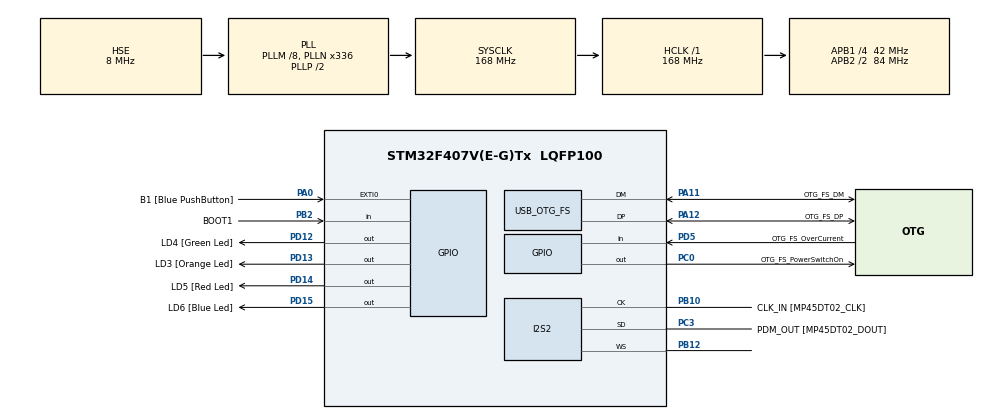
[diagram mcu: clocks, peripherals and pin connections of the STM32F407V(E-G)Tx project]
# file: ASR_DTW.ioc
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Dma.Request0=SPI2_RX
Dma.SPI2_RX.0.Channel=DMA_CHANNEL_0
Dma.SPI2_RX.0.Direction=DMA_PERIPH_TO_MEMORY
Dma.SPI2_RX.0.FIFOMode=DMA_FIFOMODE_DISABLE
Dma.SPI2_RX.0.Instance=DMA1_Stream3
Dma.SPI2_RX.0.MemDataAlignment=DMA_MDATAALIGN_HALFWORD
Dma.SPI2_RX.0.MemInc=DMA_MINC_ENABLE
Dma.SPI2_RX.0.Mode=DMA_CIRCULAR
Dma.SPI2_RX.0.PeriphDataAlignment=DMA_PDATAALIGN_HALFWORD
Dma.SPI2_RX.0.PeriphInc=DMA_PINC_DISABLE
Dma.SPI2_RX.0.Priority=DMA_PRIORITY_HIGH
FATFS._FS_LOCK=20
FATFS._FS_RPATH=2
FATFS._USE_LFN=3
FREERTOS.Tasks01=defaultTask,0,128,StartDefaultTask
FREERTOS.configCHECK_FOR_STACK_OVERFLOW=1
FREERTOS.configTOTAL_HEAP_SIZE=81920
I2S2.AudioFreq=I2S_AUDIOFREQ_32K
I2S2.ErrorAudioFreq=0.0 %
I2S2.Mode=I2S_MODE_MASTER_RX
I2S2.RealAudioFreq=32.001 KHz
I2S2.Standard=I2S_STANDARD_LSB
Mcu.Family=STM32F4
Mcu.Name=STM32F407V(E-G)Tx
Mcu.Package=LQFP100
NVIC.DMA1_Stream3_IRQn=true\:5\:0\:true
NVIC.EXTI0_IRQn=true\:15\:0\:true
NVIC.OTG_FS_IRQn=true\:6\:0\:true
NVIC.PriorityGroup=NVIC_PRIORITYGROUP_4
PA0-WKUP.GPIO_Label=B1 [Blue PushButton]
PA0-WKUP.GPIO_ModeDefaultEXTI=GPIO_MODE_IT_RISING_FALLING
PA0-WKUP.GPIO_PuPd=GPIO_NOPULL
PA0-WKUP.Signal=GPXTI0
PA11.GPIO_Label=OTG_FS_DM
PA11.GPIO_Mode=GPIO_MODE_AF_PP
PA11.GPIO_PuPd=GPIO_NOPULL
PA11.GPIO_Speed=GPIO_SPEED_HIGH
PA11.Mode=Host_Only
PA11.Signal=USB_OTG_FS_DM
PA12.GPIO_Label=OTG_FS_DP
PA12.GPIO_Mode=GPIO_MODE_AF_PP
PA12.GPIO_PuPd=GPIO_NOPULL
PA12.GPIO_Speed=GPIO_SPEED_HIGH
PA12.Mode=Host_Only
PA12.Signal=USB_OTG_FS_DP
PA13.GPIO_Label=SWDIO
PA13.Mode=Trace-Asynchronous_SW
PA13.Signal=SYS_JTMS-SWDIO
PA14.GPIO_Label=SWCLK
PA14.Mode=Trace-Asynchronous_SW
PA14.Signal=SYS_JTCK-SWCLK
PB10.GPIO_Label=CLK_IN [MP45DT02_CLK]
PB10.GPIO_Mode=GPIO_MODE_AF_PP
PB10.GPIO_PuPd=GPIO_NOPULL
PB10.GPIO_Speed=GPIO_SPEED_FAST
PB10.Mode=Half_Duplex_Master
PB10.Signal=I2S2_CK
PB12.Mode=Half_Duplex_Master
PB12.Signal=I2S2_WS
PB2.GPIO_Label=BOOT1
PB2.GPIO_Mode=GPIO_MODE_INPUT
PB2.GPIO_PuPd=GPIO_NOPULL
PB2.Signal=GPIO_Input
PB3.GPIO_Label=SWO
PB3.Mode=Trace-Asynchronous_SW
PB3.Signal=SYS_JTDO-SWO
PC0.GPIO_Label=OTG_FS_PowerSwitchOn
PC0.GPIO_ModeDefaultOutputPP=GPIO_MODE_OUTPUT_PP
PC0.GPIO_PuPd=GPIO_NOPULL
PC0.GPIO_Speed=GPIO_SPEED_LOW
PC0.Signal=GPIO_Output
PC3.GPIO_Label=PDM_OUT [MP45DT02_DOUT]
PC3.GPIO_Mode=GPIO_MODE_AF_PP
PC3.GPIO_PuPd=GPIO_NOPULL
PC3.GPIO_Speed=GPIO_SPEED_FAST
PC3.Mode=Half_Duplex_Master
PC3.Signal=I2S2_SD
PD12.GPIO_Label=LD4 [Green Led]
PD12.GPIO_ModeDefaultOutputPP=GPIO_MODE_OUTPUT_PP
PD12.GPIO_PuPd=GPIO_NOPULL
PD12.GPIO_Speed=GPIO_SPEED_LOW
PD12.Signal=GPIO_Output
PD13.GPIO_Label=LD3 [Orange Led]
PD13.GPIO_ModeDefaultOutputPP=GPIO_MODE_OUTPUT_PP
PD13.GPIO_PuPd=GPIO_NOPULL
PD13.GPIO_Speed=GPIO_SPEED_LOW
PD13.Signal=GPIO_Output
PD14.GPIO_Label=LD5 [Red Led]
PD14.GPIO_ModeDefaultOutputPP=GPIO_MODE_OUTPUT_PP
PD14.GPIO_PuPd=GPIO_NOPULL
PD14.GPIO_Speed=GPIO_SPEED_LOW
PD14.Signal=GPIO_Output
PD15.GPIO_Label=LD6 [Blue Led]
PD15.GPIO_ModeDefaultOutputPP=GPIO_MODE_OUTPUT_PP
PD15.GPIO_PuPd=GPIO_NOPULL
PD15.GPIO_Speed=GPIO_SPEED_LOW
PD15.Signal=GPIO_Output
PD5.GPIO_Label=OTG_FS_OverCurrent
PD5.GPIO_Mode=GPIO_MODE_INPUT
PD5.GPIO_PuPd=GPIO_NOPULL
PD5.Signal=GPIO_Input
PH0-OSC_IN.GPIO_Label=PH0-OSC_IN
PH0-OSC_IN.Mode=HSE-External-Oscillator
PH0-OSC_IN.Signal=RCC_OSC_IN
PH1-OSC_OUT.GPIO_Label=PH1-OSC_OUT
PH1-OSC_OUT.Mode=HSE-External-Oscillator
PH1-OSC_OUT.Signal=RCC_OSC_OUT
ProjectManager.TargetToolchain=MDK-ARM V5
RCC.48MHZClocksFreq_Value=48000000
RCC.AHBFreq_Value=168000000
RCC.APB1CLKDivider=RCC_HCLK_DIV4
RCC.APB1Freq_Value=42000000
RCC.APB1TimFreq_Value=84000000
RCC.APB2CLKDivider=RCC_HCLK_DIV2
RCC.APB2Freq_Value=84000000
RCC.APB2TimFreq_Value=168000000
RCC.CortexFreq_Value=168000000
RCC.HCLKFreq_Value=168000000
RCC.HSE_VALUE=8000000
RCC.HSI_VALUE=16000000
RCC.LSE_VALUE=32768
RCC.PLLI2SN=213
RCC.PLLM=8
RCC.PLLN=336
RCC.PLLQ=7
RCC.SYSCLKFreq_VALUE=168000000
RCC.SYSCLKSource=RCC_SYSCLKSOURCE_PLLCLK
RCC.VCOOutputFreq_Value=336000000
USB_HOST.USBH_DEBUG_LEVEL=0
USB_HOST.USBH_HandleTypeDef-MSC_FS=hUsbHostFS
USB_HOST.VirtualModeFS=Msc
USB_OTG_FS.phy_itface=HCD_PHY_EMBEDDED
VP_FATFS_VS_USB.Mode=USB
VP_FREERTOS_VS_ENABLE.Mode=Enabled
VP_USB_HOST_VS_USB_HOST_MSC_FS.Mode=MSC_FS

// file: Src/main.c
/**
  ******************************************************************************
  * File Name          : main.c
  * Date               : 03/05/2015 13:56:12
  * Description        : Main program body
  ******************************************************************************
  *
  * COPYRIGHT(c) 2015 STMicroelectronics
  *
  * Redistribution and use in source and binary forms, with or without modification,
  * are permitted provided that the following conditions are met:
  *   1. Redistributions of source code must retain the above copyright notice,
  *      this list of conditions and the following disclaimer.
  *   2. Redistributions in binary form must reproduce the above copyright notice,
  *      this list of conditions and the following disclaimer in the documentation
  *      and/or other materials provided with the distribution.
  *   3. Neither the name of STMicroelectronics nor the names of its contributors
  *      may be used to endorse or promote products derived from this software
  *      without specific prior written permission.
  *
  * THIS SOFTWARE IS PROVIDED BY THE COPYRIGHT HOLDERS AND CONTRIBUTORS "AS IS"
  * AND ANY EXPRESS OR IMPLIED WARRANTIES, INCLUDING, BUT NOT LIMITED TO, THE
  * IMPLIED WARRANTIES OF MERCHANTABILITY AND FITNESS FOR A PARTICULAR PURPOSE ARE
  * DISCLAIMED. IN NO EVENT SHALL THE COPYRIGHT HOLDER OR CONTRIBUTORS BE LIABLE
  * FOR ANY DIRECT, INDIRECT, INCIDENTAL, SPECIAL, EXEMPLARY, OR CONSEQUENTIAL
  * DAMAGES (INCLUDING, BUT NOT LIMITED TO, PROCUREMENT OF SUBSTITUTE GOODS OR
  * SERVICES; LOSS OF USE, DATA, OR PROFITS; OR BUSINESS INTERRUPTION) HOWEVER
  * CAUSED AND ON ANY THEORY OF LIABILITY, WHETHER IN CONTRACT, STRICT LIABILITY,
  * OR TORT (INCLUDING NEGLIGENCE OR OTHERWISE) ARISING IN ANY WAY OUT OF THE USE
  * OF THIS SOFTWARE, EVEN IF ADVISED OF THE POSSIBILITY OF SUCH DAMAGE.
  *
  ******************************************************************************
  */

#include "stm32f4xx_hal.h"
#include "cmsis_os.h"
#include "dma.h"
#include "fatfs.h"
#include "i2s.h"
#include "usb_host.h"
#include "gpio.h"

/* USER CODE BEGIN Includes */
#include "error_handler.h"
#include "misc.h"
/* USER CODE END Includes */

void SystemClock_Config(void);
void MX_FREERTOS_Init(void);

int main(void)
{

  /* MCU Configuration----------------------------------------------------------*/

  /* Reset of all peripherals, Initializes the Flash interface and the Systick. */
  HAL_Init();

  /* Configure the system clock */
  SystemClock_Config();

  /* Initialize all configured peripherals */
  MX_GPIO_Init();
  MX_DMA_Init();
  MX_I2S2_Init();

  /* Call init function for freertos objects (in freertos.c) */
  MX_FREERTOS_Init();

  /* Start scheduler */
  osKernelStart();

  /* We should never get here as control is now taken by the scheduler */

  /* Infinite loop */
  /* USER CODE BEGIN WHILE */
  while (1)
  {
  /* USER CODE BEGIN 3 */

	/* USER CODE END 3 */
  }

  /* USER CODE END WHILE */

}

/** System Clock Configuration
*/
void SystemClock_Config(void)
{

  RCC_OscInitTypeDef RCC_OscInitStruct;
  RCC_ClkInitTypeDef RCC_ClkInitStruct;
  RCC_PeriphCLKInitTypeDef PeriphClkInitStruct;

  __PWR_CLK_ENABLE();

  __HAL_PWR_VOLTAGESCALING_CONFIG(PWR_REGULATOR_VOLTAGE_SCALE1);

  RCC_OscInitStruct.OscillatorType = RCC_OSCILLATORTYPE_HSE;
  RCC_OscInitStruct.HSEState = RCC_HSE_ON;
  RCC_OscInitStruct.PLL.PLLState = RCC_PLL_ON;
  RCC_OscInitStruct.PLL.PLLSource = RCC_PLLSOURCE_HSE;
  RCC_OscInitStruct.PLL.PLLM = 8;
  RCC_OscInitStruct.PLL.PLLN = 336;
  RCC_OscInitStruct.PLL.PLLP = RCC_PLLP_DIV2;
  RCC_OscInitStruct.PLL.PLLQ = 7;
  HAL_RCC_OscConfig(&RCC_OscInitStruct);

  RCC_ClkInitStruct.ClockType = RCC_CLOCKTYPE_SYSCLK|RCC_CLOCKTYPE_PCLK1
                              |RCC_CLOCKTYPE_PCLK2;
  RCC_ClkInitStruct.SYSCLKSource = RCC_SYSCLKSOURCE_PLLCLK;
  RCC_ClkInitStruct.AHBCLKDivider = RCC_SYSCLK_DIV1;
  RCC_ClkInitStruct.APB1CLKDivider = RCC_HCLK_DIV4;
  RCC_ClkInitStruct.APB2CLKDivider = RCC_HCLK_DIV2;
  HAL_RCC_ClockConfig(&RCC_ClkInitStruct, FLASH_LATENCY_5);

  PeriphClkInitStruct.PeriphClockSelection = RCC_PERIPHCLK_I2S;
  PeriphClkInitStruct.PLLI2S.PLLI2SN = 213;
  PeriphClkInitStruct.PLLI2S.PLLI2SR = 2;
  HAL_RCCEx_PeriphCLKConfig(&PeriphClkInitStruct);

}

#ifdef USE_FULL_ASSERT

/**
   * @brief Reports the name of the source file and the source line number
   * where the assert_param error has occurred.
   * @param file: pointer to the source file name
   * @param line: assert_param error line source number
   * @retval None
   */
void assert_failed(uint8_t* file, uint32_t line)
{
  /* USER CODE BEGIN 6 */

	char msg[200];
  /* User can add his own implementation to report the file name and line number,
    ex: printf("Wrong parameters value: file %s on line %d\r\n", file, line) */

	sprintf(msg,"Wrong parameters value: file %s on line %d\r\n", file, line);

	Error_Handler(msg);
  /* USER CODE END 6 */
}

#endif

/************************ (C) COPYRIGHT STMicroelectronics *****END OF FILE****/

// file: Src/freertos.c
/**
  ******************************************************************************
  * File Name          : freertos.c
  * Date               : 03/05/2015 13:56:09
  * Description        : Code for freertos applications
  ******************************************************************************
  *
  * COPYRIGHT(c) 2015 STMicroelectronics
  *
  * Redistribution and use in source and binary forms, with or without modification,
  * are permitted provided that the following conditions are met:
  *   1. Redistributions of source code must retain the above copyright notice,
  *      this list of conditions and the following disclaimer.
  *   2. Redistributions in binary form must reproduce the above copyright notice,
  *      this list of conditions and the following disclaimer in the documentation
  *      and/or other materials provided with the distribution.
  *   3. Neither the name of STMicroelectronics nor the names of its contributors
  *      may be used to endorse or promote products derived from this software
  *      without specific prior written permission.
  *
  * THIS SOFTWARE IS PROVIDED BY THE COPYRIGHT HOLDERS AND CONTRIBUTORS "AS IS"
  * AND ANY EXPRESS OR IMPLIED WARRANTIES, INCLUDING, BUT NOT LIMITED TO, THE
  * IMPLIED WARRANTIES OF MERCHANTABILITY AND FITNESS FOR A PARTICULAR PURPOSE ARE
  * DISCLAIMED. IN NO EVENT SHALL THE COPYRIGHT HOLDER OR CONTRIBUTORS BE LIABLE
  * FOR ANY DIRECT, INDIRECT, INCIDENTAL, SPECIAL, EXEMPLARY, OR CONSEQUENTIAL
  * DAMAGES (INCLUDING, BUT NOT LIMITED TO, PROCUREMENT OF SUBSTITUTE GOODS OR
  * SERVICES; LOSS OF USE, DATA, OR PROFITS; OR BUSINESS INTERRUPTION) HOWEVER
  * CAUSED AND ON ANY THEORY OF LIABILITY, WHETHER IN CONTRACT, STRICT LIABILITY,
  * OR TORT (INCLUDING NEGLIGENCE OR OTHERWISE) ARISING IN ANY WAY OUT OF THE USE
  * OF THIS SOFTWARE, EVEN IF ADVISED OF THE POSSIBILITY OF SUCH DAMAGE.
  *
  ******************************************************************************
  */

#include "FreeRTOS.h"
#include "task.h"
#include "cmsis_os.h"

/* USER CODE BEGIN Includes */
#include <Error_Handler.h>
/* USER CODE END Includes */

osThreadId defaultTaskHandle;

void StartDefaultTask(void const * argument);

extern void MX_FATFS_Init(void);
extern void MX_USB_HOST_Init(void);
void MX_FREERTOS_Init(void); /* (MISRA C 2004 rule 8.1) */

/* USER CODE BEGIN FunctionPrototypes */
extern void Configure_Application(void);
/* USER CODE END FunctionPrototypes */
/* Hook prototypes */
void vApplicationStackOverflowHook(xTaskHandle xTask, signed char *pcTaskName);

/* USER CODE BEGIN 4 */
void vApplicationStackOverflowHook(xTaskHandle xTask, signed char *pcTaskName)
{
   /* Run time stack overflow checking is performed if
   configCHECK_FOR_STACK_OVERFLOW is defined to 1 or 2. This hook function is
   called if a stack overflow is detected. */
	char msg[80];

	sprintf (msg,"Stack overflow en %s\n", pcTaskName);
	Error_Handler(msg);

}
/* USER CODE END 4 */

/* Init FreeRTOS */

void MX_FREERTOS_Init(void) {
  /* USER CODE BEGIN Init */
	Configure_Application();
  /* USER CODE END Init */

  /* Create the thread(s) */
  /* definition and creation of defaultTask */
  osThreadDef(defaultTask, StartDefaultTask, osPriorityNormal, 0, 128);
  defaultTaskHandle = osThreadCreate(osThread(defaultTask), NULL);

}

/* StartDefaultTask function */
void StartDefaultTask(void const * argument)
{
  /* init code for FATFS */
  MX_FATFS_Init();

  /* init code for USB_HOST */
  MX_USB_HOST_Init();

  /* USER CODE BEGIN StartDefaultTask */
  /* Infinite loop */
  for(;;)
  {

		osThreadTerminate(osThreadGetId());
  }
  /* USER CODE END StartDefaultTask */
}

/************************ (C) COPYRIGHT STMicroelectronics *****END OF FILE****/
